# STM32F302xC register map
File version: 1.0
Registers are 32-bit, read-write, reset 0x0 unless marked. A register's access mark holds for its fields unless they carry their own. Offsets are from the block's base; [hi:lo] are bit positions; lines under a group give offsets from that group; {n}, {i} and the like mark numbered series.

## GPIOA — General Purpose I/O
Base 0x48000000
Same registers: GPIOB 0x48000400, GPIOC 0x48000800, GPIOD 0x48000C00, GPIOE 0x48001000, GPIOF 0x48001400
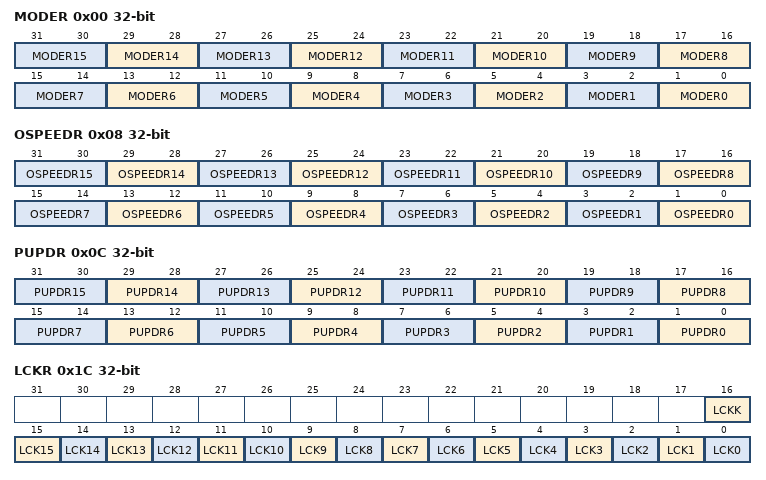
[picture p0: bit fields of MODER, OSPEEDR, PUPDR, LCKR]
0x00 MODER — GPIO port mode register
  [2n+1:2n] MODER{n} (n=0..15)
0x04 OTYPER — GPIO port output type register
0x08 OSPEEDR — GPIO port output speed register
  [2n+1:2n] OSPEEDR{n} (n=0..15)
0x0C PUPDR — GPIO port pull-up/pull-down register
  [2n+1:2n] PUPDR{n} (n=0..15)
0x10 IDR — GPIO port input data register
0x14 ODR — GPIO port output data register
0x18 BSRR — GPIO port bit set/reset register
0x1C LCKR — GPIO port configuration lock register
  [16] LCKK, [n] LCK{n} (n=0..15)
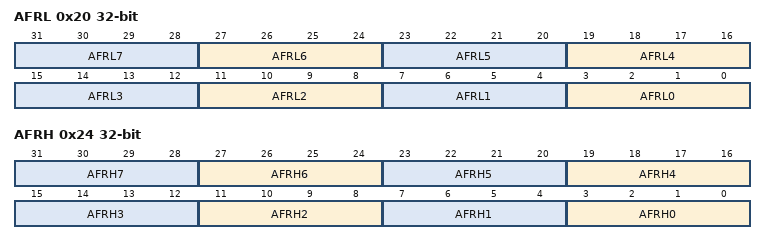
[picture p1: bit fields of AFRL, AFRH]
0x20 AFRL — GPIO alternate function registers
  [4n+3:4n] AFRL{n} (n=0..7)
0x24 AFRH — GPIO alternate function registers
  [4n+3:4n] AFRH{n} (n=0..7)
0x28 BRR — GPIO bit reset register

## ADC12_COMMON
Base 0x50000300
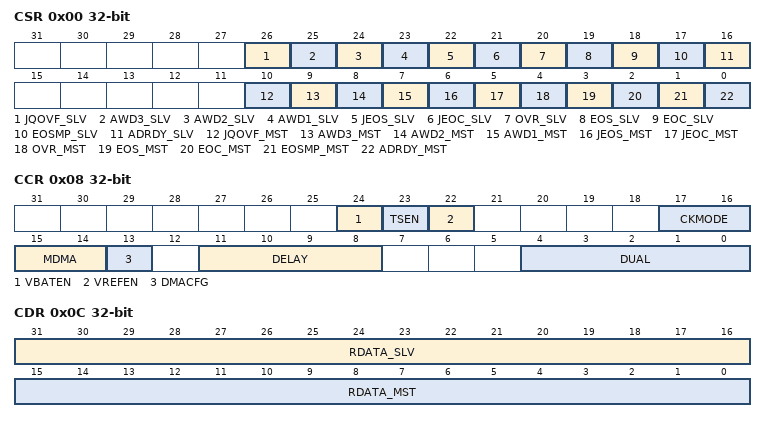
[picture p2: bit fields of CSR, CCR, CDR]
0x00 CSR — ADC Common status register
  [26] JQOVF_SLV — ADC multimode slave group injected contexts queue overflow flag
  [25] AWD3_SLV — ADC multimode slave analog watchdog 3 flag
  [24] AWD2_SLV — ADC multimode slave analog watchdog 2 flag
  [23] AWD1_SLV — ADC multimode slave analog watchdog 1 flag
  [22] JEOS_SLV — ADC multimode slave group injected end of sequence conversions flag
  [21] JEOC_SLV — ADC multimode slave group injected end of unitary conversion flag
  [20] OVR_SLV — ADC multimode slave group regular overrun flag
  [19] EOS_SLV — ADC multimode slave group regular end of sequence conversions flag
  [18] EOC_SLV — ADC multimode slave group regular end of unitary conversion flag
  [17] EOSMP_SLV — ADC multimode slave group regular end of sampling flag
  [16] ADRDY_SLV — ADC multimode slave ready flag
  [10] JQOVF_MST — ADC multimode master group injected contexts queue overflow flag
  [9] AWD3_MST — ADC multimode master analog watchdog 3 flag
  [8] AWD2_MST — ADC multimode master analog watchdog 2 flag
  [7] AWD1_MST — ADC multimode master analog watchdog 1 flag
  [6] JEOS_MST — ADC multimode master group injected end of sequence conversions flag
  [5] JEOC_MST — ADC multimode master group injected end of unitary conversion flag
  [4] OVR_MST — ADC multimode master group regular overrun flag
  [3] EOS_MST — ADC multimode master group regular end of sequence conversions flag
  [2] EOC_MST — ADC multimode master group regular end of unitary conversion flag
  [1] EOSMP_MST — ADC multimode master group regular end of sampling flag
  [0] ADRDY_MST — ADC multimode master ready flag
0x08 CCR — ADC common control register
  [24] VBATEN — ADC internal path to battery voltage enable
  [23] TSEN — ADC internal path to temperature sensor enable
  [22] VREFEN — ADC internal path to VrefInt enable
  [17:16] CKMODE — ADC common clock source and prescaler (prescaler only for clock source synchronous)
    1=SYNC_PCLK_DIV1 (ADC synchronous clock derived from AHB clock without prescaler); 2=SYNC_PCLK_DIV2 (ADC synchronous clock derived from AHB clock with prescaler division by 2); 3=SYNC_PCLK_DIV4 (ADC synchronous clock derived from AHB clock with prescaler division by 4); 0=ASYNC_DIV1 (ADC asynchronous clock without prescaler)
  [15:14] MDMA — ADC multimode DMA transfer enable
  [13] DMACFG — ADC multimode DMA transfer configuration
  [11:8] DELAY — ADC multimode delay between 2 sampling phases
    0=DELAY_1CYCLE (ADC multimode delay between two sampling phases: 1 ADC clock cycle); {v}=DELAY_{v+1}CYCLES (ADC multimode delay between two sampling phases: {v+1} ADC clock cycles) (v=1..11)
  [4:0] DUAL — ADC multimode mode selection
    0=INDEPENDENT (ADC dual mode disabled (ADC independent mode)); 6=DUAL_REG_SIMULT (ADC dual mode enabled: group regular simultaneous); 7=DUAL_REG_INTERL (ADC dual mode enabled: Combined group regular interleaved); 5=DUAL_INJ_SIMULT (ADC dual mode enabled: group injected simultaneous); 9=DUAL_INJ_ALTERN (ADC dual mode enabled: group injected alternate trigger. Works only with external triggers (not internal SW start)); 1=DUAL_REG_SIM_INJ_SIM (ADC dual mode enabled: Combined group regular simultaneous + group injected simultaneous); 2=DUAL_REG_SIM_INJ_ALT (ADC dual mode enabled: Combined group regular simultaneous + group injected alternate trigger); 3=DUAL_REG_INT_INJ_SIM (ADC dual mode enabled: Combined group regular interleaved + group injected simultaneous)
0x0C CDR — ADC common regular data register for dual AND triple modes
  [31:16] RDATA_SLV — ADC multimode slave group regular conversion data
  [15:0] RDATA_MST — ADC multimode master group regular conversion data

## DBGMCU — Debug MCU
Base 0xE0042000
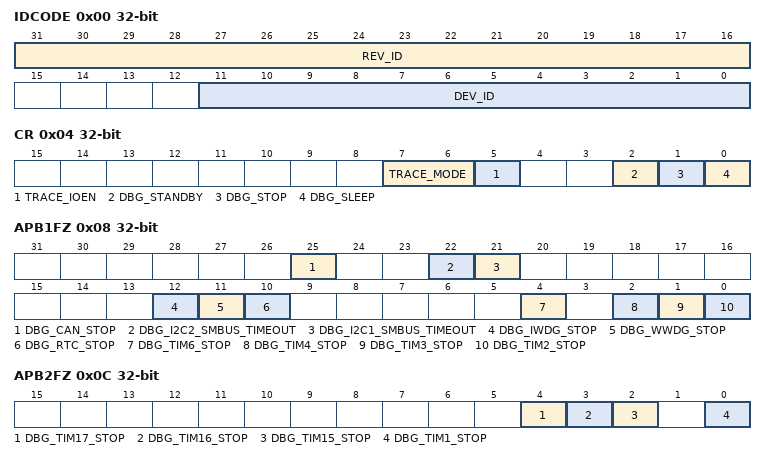
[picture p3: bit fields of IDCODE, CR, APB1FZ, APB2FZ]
0x00 IDCODE — MCU device ID code
  [31:16] REV_ID, [11:0] DEV_ID
0x04 CR — Debug MCU configuration register
  [7:6] TRACE_MODE, [5] TRACE_IOEN, [2] DBG_STANDBY, [1] DBG_STOP, [0] DBG_SLEEP
0x08 APB1FZ — Debug MCU APB1 freeze register
  [25] DBG_CAN_STOP, [22] DBG_I2C2_SMBUS_TIMEOUT, [21] DBG_I2C1_SMBUS_TIMEOUT, [12] DBG_IWDG_STOP, [11] DBG_WWDG_STOP, [10] DBG_RTC_STOP, [4] DBG_TIM6_STOP, [2] DBG_TIM4_STOP, [1] DBG_TIM3_STOP, [0] DBG_TIM2_STOP
0x0C APB2FZ — Debug MCU APB2 freeze register
  [4] DBG_TIM17_STOP, [3] DBG_TIM16_STOP, [2] DBG_TIM15_STOP, [0] DBG_TIM1_STOP
